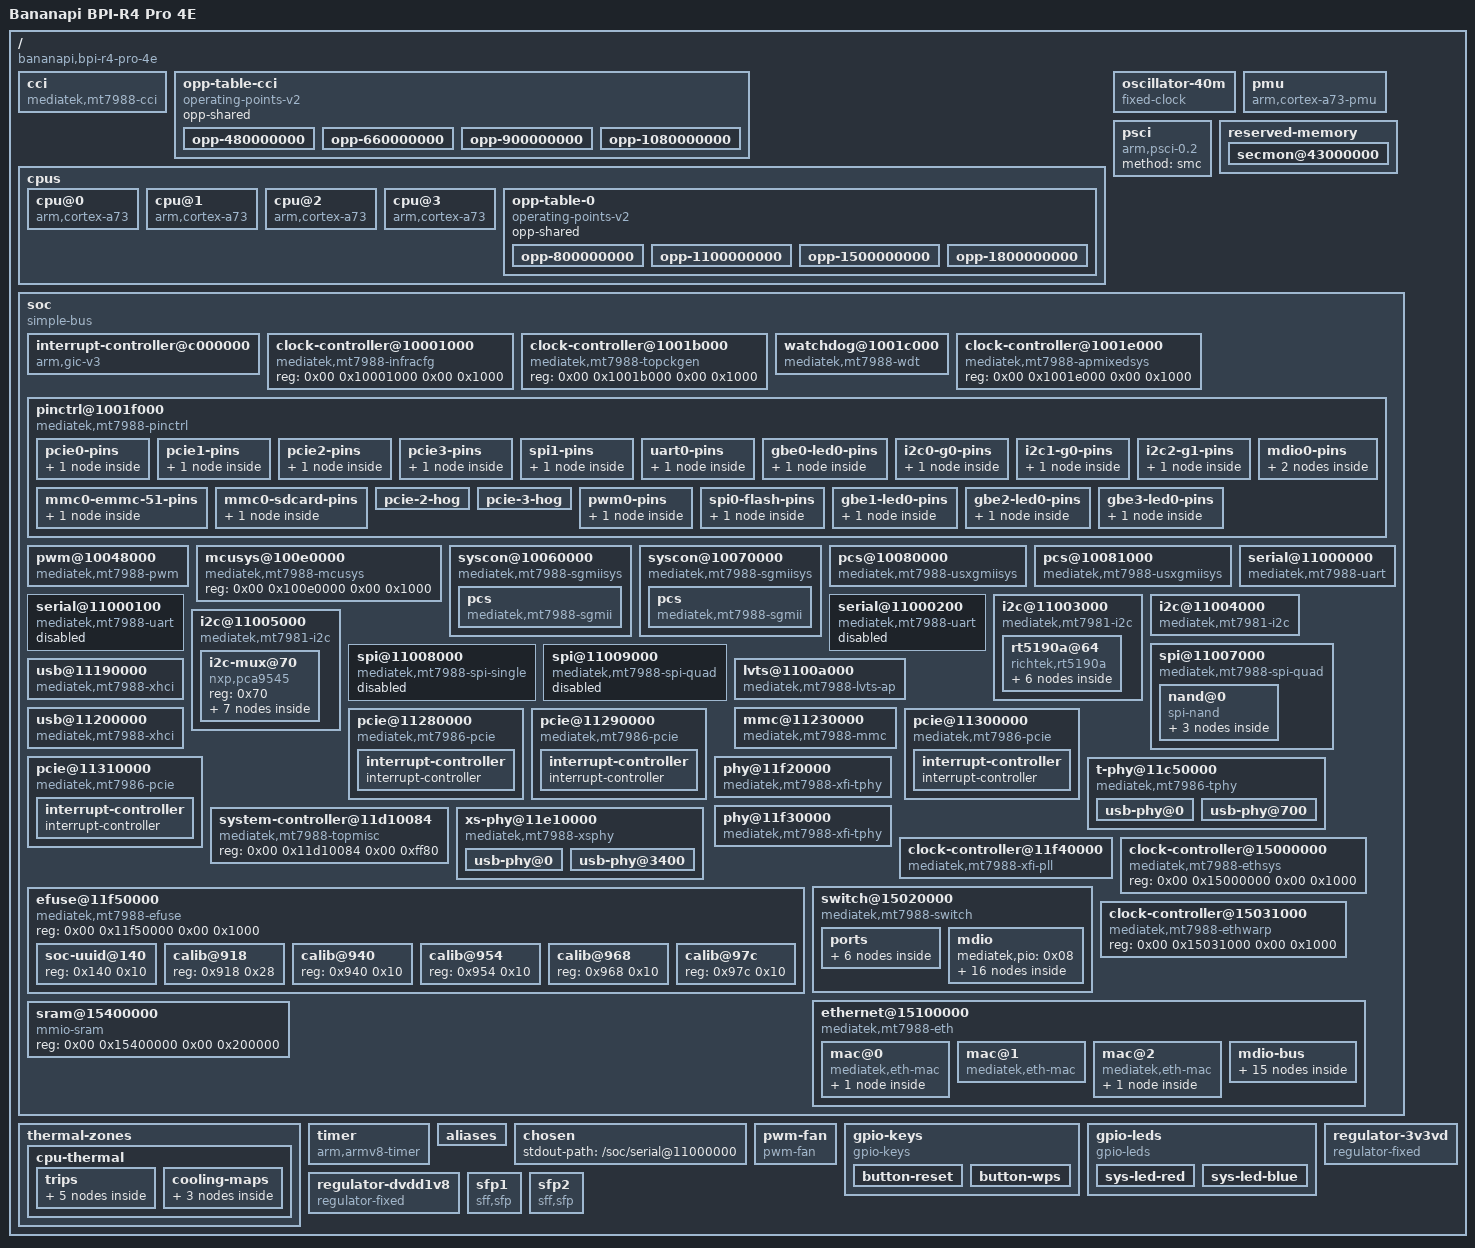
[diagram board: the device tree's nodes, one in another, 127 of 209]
/dts-v1/;

/ {
	compatible = "bananapi,bpi-r4-pro-4e", "bananapi,bpi-r4-pro", "mediatek,mt7988a";
	interrupt-parent = <0x01>;
	#address-cells = <0x02>;
	#size-cells = <0x02>;
	model = "Bananapi BPI-R4 Pro 4E";

	cci {
		compatible = "mediatek,mt7988-cci", "mediatek,mt8183-cci";
		clocks = <0x02 0x00 0x03 0x00>;
		clock-names = "cci", "intermediate";
		operating-points-v2 = <0x04>;
		proc-supply = <0x05>;
		phandle = <0x07>;
	};

	opp-table-cci {
		compatible = "operating-points-v2";
		opp-shared;
		phandle = <0x04>;

		opp-480000000 {
			opp-hz = <0x00 0x1c9c3800>;
			opp-microvolt = <0xcf850>;
		};

		opp-660000000 {
			opp-hz = <0x00 0x2756cd00>;
			opp-microvolt = <0xcf850>;
		};

		opp-900000000 {
			opp-hz = <0x00 0x35a4e900>;
			opp-microvolt = <0xcf850>;
		};

		opp-1080000000 {
			opp-hz = <0x00 0x405f7e00>;
			opp-microvolt = <0xdbba0>;
		};
	};

	cpus {
		#address-cells = <0x01>;
		#size-cells = <0x00>;

		cpu@0 {
			compatible = "arm,cortex-a73";
			reg = <0x00>;
			device_type = "cpu";
			enable-method = "psci";
			clocks = <0x02 0x01 0x03 0x00>;
			clock-names = "cpu", "intermediate";
			operating-points-v2 = <0x06>;
			mediatek,cci = <0x07>;
			proc-supply = <0x05>;
			phandle = <0x41>;
		};

		cpu@1 {
			compatible = "arm,cortex-a73";
			reg = <0x01>;
			device_type = "cpu";
			enable-method = "psci";
			clocks = <0x02 0x01 0x03 0x00>;
			clock-names = "cpu", "intermediate";
			operating-points-v2 = <0x06>;
			mediatek,cci = <0x07>;
			proc-supply = <0x05>;
			phandle = <0x42>;
		};

		cpu@2 {
			compatible = "arm,cortex-a73";
			reg = <0x02>;
			device_type = "cpu";
			enable-method = "psci";
			clocks = <0x02 0x01 0x03 0x00>;
			clock-names = "cpu", "intermediate";
			operating-points-v2 = <0x06>;
			mediatek,cci = <0x07>;
			proc-supply = <0x05>;
			phandle = <0x43>;
		};

		cpu@3 {
			compatible = "arm,cortex-a73";
			reg = <0x03>;
			device_type = "cpu";
			enable-method = "psci";
			clocks = <0x02 0x01 0x03 0x00>;
			clock-names = "cpu", "intermediate";
			operating-points-v2 = <0x06>;
			mediatek,cci = <0x07>;
			proc-supply = <0x05>;
			phandle = <0x44>;
		};

		opp-table-0 {
			compatible = "operating-points-v2";
			opp-shared;
			phandle = <0x06>;

			opp-800000000 {
				opp-hz = <0x00 0x2faf0800>;
				opp-microvolt = <0xcf850>;
			};

			opp-1100000000 {
				opp-hz = <0x00 0x4190ab00>;
				opp-microvolt = <0xcf850>;
			};

			opp-1500000000 {
				opp-hz = <0x00 0x59682f00>;
				opp-microvolt = <0xcf850>;
			};

			opp-1800000000 {
				opp-hz = <0x00 0x6b49d200>;
				opp-microvolt = <0xdbba0>;
			};
		};
	};

	oscillator-40m {
		compatible = "fixed-clock";
		clock-frequency = <0x2625a00>;
		#clock-cells = <0x00>;
		clock-output-names = "clkxtal";
	};

	pmu {
		compatible = "arm,cortex-a73-pmu";
		interrupt-parent = <0x01>;
		interrupts = <0x01 0x07 0x08>;
	};

	psci {
		compatible = "arm,psci-0.2";
		method = "smc";
	};

	reserved-memory {
		#address-cells = <0x02>;
		#size-cells = <0x02>;
		ranges;

		secmon@43000000 {
			reg = <0x00 0x43000000 0x00 0x50000>;
			no-map;
		};
	};

	soc {
		compatible = "simple-bus";
		ranges;
		#address-cells = <0x02>;
		#size-cells = <0x02>;

		interrupt-controller@c000000 {
			compatible = "arm,gic-v3";
			reg = <0x00 0xc000000 0x00 0x40000 0x00 0xc080000 0x00 0x200000 0x00 0xc400000 0x00 0x2000 0x00 0xc410000 0x00 0x1000 0x00 0xc420000 0x00 0x2000>;
			interrupt-parent = <0x01>;
			interrupts = <0x01 0x09 0x04>;
			interrupt-controller;
			#interrupt-cells = <0x03>;
			phandle = <0x01>;
		};

		clock-controller@10001000 {
			compatible = "mediatek,mt7988-infracfg", "syscon";
			reg = <0x00 0x10001000 0x00 0x1000>;
			#clock-cells = <0x01>;
			#reset-cells = <0x01>;
			phandle = <0x09>;
		};

		clock-controller@1001b000 {
			compatible = "mediatek,mt7988-topckgen", "syscon";
			reg = <0x00 0x1001b000 0x00 0x1000>;
			#clock-cells = <0x01>;
			phandle = <0x03>;
		};

		watchdog@1001c000 {
			compatible = "mediatek,mt7988-wdt";
			reg = <0x00 0x1001c000 0x00 0x1000>;
			interrupts = <0x00 0x6e 0x04>;
			#reset-cells = <0x01>;
			status = "okay";
			phandle = <0x21>;
		};

		clock-controller@1001e000 {
			compatible = "mediatek,mt7988-apmixedsys";
			reg = <0x00 0x1001e000 0x00 0x1000>;
			#clock-cells = <0x01>;
			phandle = <0x15>;
		};

		pinctrl@1001f000 {
			compatible = "mediatek,mt7988-pinctrl";
			reg = <0x00 0x1001f000 0x00 0x1000 0x00 0x11c10000 0x00 0x1000 0x00 0x11d00000 0x00 0x1000 0x00 0x11d20000 0x00 0x1000 0x00 0x11e00000 0x00 0x1000 0x00 0x11f00000 0x00 0x1000 0x00 0x1000b000 0x00 0x1000>;
			reg-names = "gpio", "iocfg_tr", "iocfg_br", "iocfg_rb", "iocfg_lb", "iocfg_tl", "eint";
			gpio-controller;
			#gpio-cells = <0x02>;
			gpio-ranges = <0x08 0x00 0x00 0x54>;
			interrupt-controller;
			interrupts = <0x00 0xe1 0x04>;
			interrupt-parent = <0x01>;
			#interrupt-cells = <0x02>;
			phandle = <0x08>;

			pcie0-pins {
				phandle = <0x1b>;

				mux {
					function = "pcie";
					groups = "pcie_2l_0_pereset", "pcie_clk_req_n0_0", "pcie_wake_n0_0";
				};
			};

			pcie1-pins {
				phandle = <0x1d>;

				mux {
					function = "pcie";
					groups = "pcie_2l_1_pereset", "pcie_clk_req_n1", "pcie_wake_n1_0";
				};
			};

			pcie2-pins {
				phandle = <0x16>;

				mux {
					function = "pcie";
					groups = "pcie_1l_0_pereset", "pcie_clk_req_n2_0", "pcie_wake_n2_0";
				};
			};

			pcie3-pins {
				phandle = <0x19>;

				mux {
					function = "pcie";
					groups = "pcie_1l_1_pereset", "pcie_clk_req_n3", "pcie_wake_n3_0";
				};
			};

			spi1-pins {
				phandle = <0x10>;

				mux {
					function = "spi";
					groups = "spi1";
				};
			};

			uart0-pins {
				phandle = <0x0a>;

				mux {
					function = "uart";
					groups = "uart0";
				};
			};

			gbe0-led0-pins {
				phandle = <0x29>;

				mux {
					function = "led";
					groups = "gbe0_led0";
				};
			};

			i2c0-g0-pins {
				phandle = <0x0b>;

				mux {
					function = "i2c";
					groups = "i2c0_1";
				};
			};

			i2c1-g0-pins {
				phandle = <0x0d>;

				mux {
					function = "i2c";
					groups = "i2c1_0";
				};
			};

			i2c2-g1-pins {
				phandle = <0x0e>;

				mux {
					function = "i2c";
					groups = "i2c2_1";
				};
			};

			mdio0-pins {
				phandle = <0x30>;

				mux {
					function = "eth";
					groups = "mdc_mdio0";
				};

				conf {
					pins = "SMI_0_MDC", "SMI_0_MDIO";
					drive-strength = <0x08>;
				};
			};

			mmc0-emmc-51-pins {
				phandle = <0x45>;

				mux {
					function = "flash";
					groups = "emmc_51";
				};
			};

			mmc0-sdcard-pins {
				phandle = <0x46>;

				mux {
					function = "flash";
					groups = "sdcard";
				};
			};

			pcie-2-hog {
				gpio-hog;
				gpios = <0x4f 0x00>;
			};

			pcie-3-hog {
				gpio-hog;
				gpios = <0x3f 0x00>;
			};

			pwm0-pins {
				phandle = <0x3c>;

				mux {
					groups = "pwm0";
					function = "pwm";
				};
			};

			spi0-flash-pins {
				phandle = <0x0f>;

				mux {
					function = "spi";
					groups = "spi0", "spi0_wp_hold";
				};
			};

			gbe1-led0-pins {
				phandle = <0x2b>;

				mux {
					function = "led";
					groups = "gbe1_led0";
				};
			};

			gbe2-led0-pins {
				phandle = <0x47>;

				mux {
					function = "led";
					groups = "gbe2_led0";
				};
			};

			gbe3-led0-pins {
				phandle = <0x48>;

				mux {
					function = "led";
					groups = "gbe3_led0";
				};
			};
		};

		pwm@10048000 {
			compatible = "mediatek,mt7988-pwm";
			reg = <0x00 0x10048000 0x00 0x1000>;
			clocks = <0x09 0x19 0x09 0x18 0x09 0x1a 0x09 0x1b 0x09 0x1c 0x09 0x1d 0x09 0x1e 0x09 0x1f 0x09 0x20 0x09 0x21>;
			clock-names = "top", "main", "pwm1", "pwm2", "pwm3", "pwm4", "pwm5", "pwm6", "pwm7", "pwm8";
			#pwm-cells = <0x02>;
			status = "okay";
			phandle = <0x3d>;
		};

		mcusys@100e0000 {
			compatible = "mediatek,mt7988-mcusys", "syscon";
			reg = <0x00 0x100e0000 0x00 0x1000>;
			#clock-cells = <0x01>;
			phandle = <0x02>;
		};

		/*
		 * SGMII / USXGMII SerDes PCS blocks.  The MACs bind these via
		 * pcs-handle; without them mtk_eth_soc logs
		 *   eth1: couldn't find a PCS for 10gbase-r
		 * and no WAN / MxL-CPU link comes up.  Node text mirrors the
		 * vendor / ly4096x board DTB.  The resets reference the
		 * TOPRGU (watchdog) reset controller (our phandle 0x21), NOT
		 * ethwarp: TOPRGU indices are SGMII0=1, SGMII1=2, XFI0=0x0c,
		 * XFI1=0x0d (MT7988_TOPRGU_SW_RST_NUM=24).
		 */
		syscon@10060000 {
			compatible = "mediatek,mt7988-sgmiisys", "mediatek,mt7988-sgmiisys0", "syscon", "simple-mfd";
			reg = <0x00 0x10060000 0x00 0x1000>;
			resets = <0x21 0x01>;
			#clock-cells = <0x01>;
			phandle = <0x80>;

			pcs {
				compatible = "mediatek,mt7988-sgmii";
				clocks = <0x03 0x43 0x80 0x00 0x80 0x01>;
				clock-names = "sgmii_sel", "sgmii_tx", "sgmii_rx";
				phys = <0x5e>;
				#pcs-cells = <0x00>;
				phandle = <0x81>;
			};
		};

		syscon@10070000 {
			compatible = "mediatek,mt7988-sgmiisys", "mediatek,mt7988-sgmiisys1", "syscon", "simple-mfd";
			reg = <0x00 0x10070000 0x00 0x1000>;
			resets = <0x21 0x02>;
			#clock-cells = <0x01>;
			phandle = <0x82>;

			pcs {
				compatible = "mediatek,mt7988-sgmii";
				clocks = <0x03 0x45 0x82 0x00 0x82 0x01>;
				clock-names = "sgmii_sel", "sgmii_tx", "sgmii_rx";
				phys = <0x5f>;
				#pcs-cells = <0x00>;
				phandle = <0x83>;
			};
		};

		pcs@10080000 {
			compatible = "mediatek,mt7988-usxgmiisys";
			reg = <0x00 0x10080000 0x00 0x1000>;
			resets = <0x21 0x0c>;
			clocks = <0x03 0x41>;
			phys = <0x5e>;
			#pcs-cells = <0x00>;
			phandle = <0x84>;
		};

		pcs@10081000 {
			compatible = "mediatek,mt7988-usxgmiisys";
			reg = <0x00 0x10081000 0x00 0x1000>;
			resets = <0x21 0x0d>;
			clocks = <0x03 0x42>;
			phys = <0x5f>;
			#pcs-cells = <0x00>;
			phandle = <0x85>;
		};

		serial@11000000 {
			compatible = "mediatek,mt7988-uart", "mediatek,mt6577-uart";
			reg = <0x00 0x11000000 0x00 0x100>;
			interrupts = <0x00 0x7b 0x04>;
			interrupt-names = "uart", "wakeup";
			clocks = <0x03 0x27 0x09 0x2f>;
			clock-names = "baud", "bus";
			pinctrl-names = "default";
			pinctrl-0 = <0x0a>;
			status = "okay";
			phandle = <0x49>;
		};

		serial@11000100 {
			compatible = "mediatek,mt7988-uart", "mediatek,mt6577-uart";
			reg = <0x00 0x11000100 0x00 0x100>;
			interrupts = <0x00 0x7c 0x04>;
			interrupt-names = "uart", "wakeup";
			clocks = <0x03 0x27 0x09 0x30>;
			clock-names = "baud", "bus";
			status = "disabled";
		};

		serial@11000200 {
			compatible = "mediatek,mt7988-uart", "mediatek,mt6577-uart";
			reg = <0x00 0x11000200 0x00 0x100>;
			interrupts = <0x00 0x7d 0x04>;
			interrupt-names = "uart", "wakeup";
			clocks = <0x03 0x27 0x09 0x31>;
			clock-names = "baud", "bus";
			status = "disabled";
		};

		i2c@11003000 {
			compatible = "mediatek,mt7981-i2c";
			reg = <0x00 0x11003000 0x00 0x1000 0x00 0x10217080 0x00 0x80>;
			interrupts = <0x00 0x88 0x04>;
			clock-div = <0x01>;
			clocks = <0x09 0x2e 0x09 0x2a>;
			clock-names = "main", "dma";
			#address-cells = <0x01>;
			#size-cells = <0x00>;
			status = "okay";
			pinctrl-0 = <0x0b>;
			pinctrl-names = "default";
			phandle = <0x4a>;

			rt5190a@64 {
				compatible = "richtek,rt5190a";
				reg = <0x64>;
				vin2-supply = <0x0c>;
				vin3-supply = <0x0c>;
				vin4-supply = <0x0c>;
				phandle = <0x4b>;

				regulators {

					buck1 {
						regulator-name = "rt5190a-buck1";
						regulator-min-microvolt = <0x4daad0>;
						regulator-max-microvolt = <0x4daad0>;
						regulator-allowed-modes = <0x00 0x01>;
						regulator-boot-on;
						regulator-always-on;
						phandle = <0x0c>;
					};

					buck2 {
						regulator-name = "vcore";
						regulator-min-microvolt = <0x927c0>;
						regulator-max-microvolt = <0x155cc0>;
						regulator-boot-on;
						regulator-always-on;
					};

					buck3 {
						regulator-name = "vproc";
						regulator-min-microvolt = <0x927c0>;
						regulator-max-microvolt = <0x155cc0>;
						regulator-boot-on;
						regulator-always-on;
						phandle = <0x05>;
					};

					buck4 {
						regulator-name = "rt5190a-buck4";
						regulator-min-microvolt = <0x1b7740>;
						regulator-max-microvolt = <0x1b7740>;
						regulator-allowed-modes = <0x00 0x01>;
						regulator-boot-on;
						regulator-always-on;
					};

					ldo {
						regulator-name = "rt5190a-ldo";
						regulator-min-microvolt = <0x1b7740>;
						regulator-max-microvolt = <0x1b7740>;
						regulator-boot-on;
						regulator-always-on;
					};
				};
			};
		};

		i2c@11004000 {
			compatible = "mediatek,mt7981-i2c";
			reg = <0x00 0x11004000 0x00 0x1000 0x00 0x10217100 0x00 0x80>;
			interrupts = <0x00 0x90 0x04>;
			clock-div = <0x01>;
			clocks = <0x09 0x2e 0x09 0x2a>;
			clock-names = "main", "dma";
			#address-cells = <0x01>;
			#size-cells = <0x00>;
			status = "okay";
			pinctrl-0 = <0x0d>;
			pinctrl-names = "default";
			phandle = <0x4c>;
		};

		i2c@11005000 {
			compatible = "mediatek,mt7981-i2c";
			reg = <0x00 0x11005000 0x00 0x1000 0x00 0x10217180 0x00 0x80>;
			interrupts = <0x00 0x91 0x04>;
			clock-div = <0x01>;
			clocks = <0x09 0x2e 0x09 0x2a>;
			clock-names = "main", "dma";
			#address-cells = <0x01>;
			#size-cells = <0x00>;
			status = "okay";
			pinctrl-0 = <0x0e>;
			pinctrl-names = "default";
			phandle = <0x4d>;

			i2c-mux@70 {
				compatible = "nxp,pca9545";
				reg = <0x70>;
				#address-cells = <0x01>;
				#size-cells = <0x00>;
				phandle = <0x4e>;

				i2c@0 {
					reg = <0x00>;
					#address-cells = <0x01>;
					#size-cells = <0x00>;
					phandle = <0x4f>;

					i2c-gpio-expander@20 {
						compatible = "nxp,pca9555";
						reg = <0x20>;
						gpio-controller;
						#gpio-cells = <0x02>;
						phandle = <0x3e>;
					};

					rtc@51 {
						compatible = "nxp,pcf8563";
						reg = <0x51>;
					};

					eeprom@57 {
						compatible = "atmel,24c02";
						reg = <0x57>;
						address-width = <0x08>;
						pagesize = <0x08>;
						size = <0x100>;
					};
				};

				i2c@1 {
					reg = <0x01>;
					#address-cells = <0x01>;
					#size-cells = <0x00>;
					phandle = <0x3f>;
				};

				i2c@2 {
					reg = <0x02>;
					#address-cells = <0x01>;
					#size-cells = <0x00>;
					phandle = <0x40>;
				};

				i2c@3 {
					reg = <0x03>;
					#address-cells = <0x01>;
					#size-cells = <0x00>;
					phandle = <0x50>;
				};
			};
		};

		spi@11007000 {
			compatible = "mediatek,mt7988-spi-quad", "mediatek,spi-ipm";
			reg = <0x00 0x11007000 0x00 0x100>;
			interrupts = <0x00 0x8c 0x04>;
			clocks = <0x03 0x04 0x03 0x2a 0x09 0x35 0x09 0x38>;
			clock-names = "parent-clk", "sel-clk", "spi-clk", "hclk";
			#address-cells = <0x01>;
			#size-cells = <0x00>;
			status = "okay";
			pinctrl-0 = <0x0f>;
			pinctrl-names = "default";
			phandle = <0x51>;

			nand@0 {
				compatible = "spi-nand";
				reg = <0x00>;
				spi-max-frequency = <0x3197500>;
				spi-rx-bus-width = <0x04>;
				spi-tx-bus-width = <0x04>;
				phandle = <0x52>;

				partitions {
					compatible = "fixed-partitions";
					#address-cells = <0x01>;
					#size-cells = <0x01>;

					partition@0 {
						reg = <0x00 0x200000>;
						label = "bl2";
					};

					partition@200000 {
						compatible = "linux,ubi";
						reg = <0x200000 0xfe00000>;
						label = "ubi";
					};
				};
			};
		};

		spi@11008000 {
			compatible = "mediatek,mt7988-spi-single", "mediatek,spi-ipm";
			reg = <0x00 0x11008000 0x00 0x100>;
			interrupts = <0x00 0x8d 0x04>;
			clocks = <0x03 0x04 0x03 0x2b 0x09 0x36 0x09 0x39>;
			clock-names = "parent-clk", "sel-clk", "spi-clk", "hclk";
			#address-cells = <0x01>;
			#size-cells = <0x00>;
			pinctrl-names = "default";
			pinctrl-0 = <0x10>;
			status = "disabled";
			phandle = <0x53>;
		};

		spi@11009000 {
			compatible = "mediatek,mt7988-spi-quad", "mediatek,spi-ipm";
			reg = <0x00 0x11009000 0x00 0x100>;
			interrupts = <0x00 0x8e 0x04>;
			clocks = <0x03 0x04 0x03 0x2a 0x09 0x37 0x09 0x3a>;
			clock-names = "parent-clk", "sel-clk", "spi-clk", "hclk";
			#address-cells = <0x01>;
			#size-cells = <0x00>;
			status = "disabled";
			phandle = <0x54>;
		};

		lvts@1100a000 {
			compatible = "mediatek,mt7988-lvts-ap";
			#thermal-sensor-cells = <0x01>;
			reg = <0x00 0x1100a000 0x00 0x1000>;
			clocks = <0x09 0x2d>;
			interrupts = <0x00 0x8a 0x04>;
			resets = <0x09 0x01>;
			nvmem-cells = <0x11>;
			nvmem-cell-names = "lvts-calib-data-1";
			phandle = <0x37>;
		};

		usb@11190000 {
			compatible = "mediatek,mt7988-xhci", "mediatek,mtk-xhci";
			reg = <0x00 0x11190000 0x00 0x2e00 0x00 0x11193e00 0x00 0x100>;
			reg-names = "mac", "ippc";
			interrupts = <0x00 0xad 0x04>;
			clocks = <0x09 0x4b 0x09 0x4d 0x09 0x49 0x09 0x47 0x09 0x55>;
			clock-names = "sys_ck", "ref_ck", "mcu_ck", "dma_ck", "xhci_ck";
			phys = <0x12 0x03>;
			status = "okay";
			mediatek,u3p-dis-msk = <0x01>;
			phandle = <0x55>;
		};

		usb@11200000 {
			compatible = "mediatek,mt7988-xhci", "mediatek,mtk-xhci";
			reg = <0x00 0x11200000 0x00 0x2e00 0x00 0x11203e00 0x00 0x100>;
			reg-names = "mac", "ippc";
			interrupts = <0x00 0xac 0x04>;
			clocks = <0x09 0x4c 0x09 0x4e 0x09 0x4a 0x09 0x48 0x09 0x56>;
			clock-names = "sys_ck", "ref_ck", "mcu_ck", "dma_ck", "xhci_ck";
			phys = <0x13 0x03 0x14 0x04>;
			status = "okay";
			phandle = <0x56>;
		};

		mmc@11230000 {
			no-mmc;
			vqmmc-supply = <0x77>;
			vmmc-supply = <0x77>;
			cap-sd-highspeed;
			max-frequency = <0x2dc6c00>;
			bus-width = <0x04>;
			cd-gpios = <0x08 0x0c 0x01>;
			pinctrl-1 = <0x46>;
			pinctrl-0 = <0x46>;
			pinctrl-names = "default", "state_uhs";
			compatible = "mediatek,mt7988-mmc";
			reg = <0x00 0x11230000 0x00 0x1000 0x00 0x11d60000 0x00 0x1000>;
			interrupts = <0x00 0x8f 0x04>;
			clocks = <0x09 0x3f 0x09 0x40 0x09 0x42 0x09 0x41>;
			assigned-clocks = <0x03 0x28 0x03 0x29>;
			assigned-clock-parents = <0x03 0x11 0x15 0x0b>;
			clock-names = "source", "hclk", "axi_cg", "ahb_cg";
			#address-cells = <0x01>;
			#size-cells = <0x00>;
			status = "okay";
			phandle = <0x57>;
		};

		pcie@11280000 {
			compatible = "mediatek,mt7986-pcie", "mediatek,mt8192-pcie";
			device_type = "pci";
			#address-cells = <0x03>;
			#size-cells = <0x02>;
			reg = <0x00 0x11280000 0x00 0x2000>;
			reg-names = "pcie-mac";
			linux,pci-domain = <0x03>;
			interrupts = <0x00 0xaa 0x04>;
			bus-range = <0x00 0xff>;
			ranges = <0x81000000 0x00 0x20000000 0x00 0x20000000 0x00 0x200000 0x82000000 0x00 0x20200000 0x00 0x20200000 0x00 0x7e00000>;
			clocks = <0x09 0x5d 0x09 0x59 0x09 0x15 0x09 0x61>;
			clock-names = "pl_250m", "tl_26m", "peri_26m", "top_133m";
			pinctrl-names = "default";
			pinctrl-0 = <0x16>;
			status = "okay";
			phys = <0x17 0x02>;
			phy-names = "pcie-phy";
			#interrupt-cells = <0x01>;
			interrupt-map-mask = <0x00 0x00 0x00 0x07>;
			interrupt-map = <0x00 0x00 0x00 0x01 0x18 0x00 0x00 0x00 0x00 0x02 0x18 0x01 0x00 0x00 0x00 0x03 0x18 0x02 0x00 0x00 0x00 0x04 0x18 0x03>;
			phandle = <0x58>;

			interrupt-controller {
				#address-cells = <0x00>;
				#interrupt-cells = <0x01>;
				interrupt-controller;
				phandle = <0x18>;
			};
		};

		pcie@11290000 {
			compatible = "mediatek,mt7986-pcie", "mediatek,mt8192-pcie";
			device_type = "pci";
			#address-cells = <0x03>;
			#size-cells = <0x02>;
			reg = <0x00 0x11290000 0x00 0x2000>;
			reg-names = "pcie-mac";
			linux,pci-domain = <0x02>;
			interrupts = <0x00 0xab 0x04>;
			bus-range = <0x00 0xff>;
			ranges = <0x81000000 0x00 0x28000000 0x00 0x28000000 0x00 0x200000 0x82000000 0x00 0x28200000 0x00 0x28200000 0x00 0x7e00000>;
			clocks = <0x09 0x5e 0x09 0x5a 0x09 0x16 0x09 0x62>;
			clock-names = "pl_250m", "tl_26m", "peri_26m", "top_133m";
			pinctrl-names = "default";
			pinctrl-0 = <0x19>;
			status = "okay";
			#interrupt-cells = <0x01>;
			interrupt-map-mask = <0x00 0x00 0x00 0x07>;
			interrupt-map = <0x00 0x00 0x00 0x01 0x1a 0x00 0x00 0x00 0x00 0x02 0x1a 0x01 0x00 0x00 0x00 0x03 0x1a 0x02 0x00 0x00 0x00 0x04 0x1a 0x03>;
			phandle = <0x59>;

			interrupt-controller {
				#address-cells = <0x00>;
				#interrupt-cells = <0x01>;
				interrupt-controller;
				phandle = <0x1a>;
			};
		};

		pcie@11300000 {
			compatible = "mediatek,mt7986-pcie", "mediatek,mt8192-pcie";
			device_type = "pci";
			#address-cells = <0x03>;
			#size-cells = <0x02>;
			reg = <0x00 0x11300000 0x00 0x2000>;
			reg-names = "pcie-mac";
			linux,pci-domain = <0x00>;
			interrupts = <0x00 0xa8 0x04>;
			bus-range = <0x00 0xff>;
			ranges = <0x81000000 0x00 0x30000000 0x00 0x30000000 0x00 0x200000 0x82000000 0x00 0x30200000 0x00 0x30200000 0x00 0x7e00000>;
			clocks = <0x09 0x5b 0x09 0x57 0x09 0x13 0x09 0x5f>;
			clock-names = "pl_250m", "tl_26m", "peri_26m", "top_133m";
			pinctrl-names = "default";
			pinctrl-0 = <0x1b>;
			status = "okay";
			#interrupt-cells = <0x01>;
			interrupt-map-mask = <0x00 0x00 0x00 0x07>;
			interrupt-map = <0x00 0x00 0x00 0x01 0x1c 0x00 0x00 0x00 0x00 0x02 0x1c 0x01 0x00 0x00 0x00 0x03 0x1c 0x02 0x00 0x00 0x00 0x04 0x1c 0x03>;
			phandle = <0x5a>;

			interrupt-controller {
				#address-cells = <0x00>;
				#interrupt-cells = <0x01>;
				interrupt-controller;
				phandle = <0x1c>;
			};
		};

		pcie@11310000 {
			compatible = "mediatek,mt7986-pcie", "mediatek,mt8192-pcie";
			device_type = "pci";
			#address-cells = <0x03>;
			#size-cells = <0x02>;
			reg = <0x00 0x11310000 0x00 0x2000>;
			reg-names = "pcie-mac";
			linux,pci-domain = <0x01>;
			interrupts = <0x00 0xa9 0x04>;
			bus-range = <0x00 0xff>;
			ranges = <0x81000000 0x00 0x38000000 0x00 0x38000000 0x00 0x200000 0x82000000 0x00 0x38200000 0x00 0x38200000 0x00 0x7e00000>;
			clocks = <0x09 0x5c 0x09 0x58 0x09 0x14 0x09 0x60>;
			clock-names = "pl_250m", "tl_26m", "peri_26m", "top_133m";
			pinctrl-names = "default";
			pinctrl-0 = <0x1d>;
			status = "okay";
			#interrupt-cells = <0x01>;
			interrupt-map-mask = <0x00 0x00 0x00 0x07>;
			interrupt-map = <0x00 0x00 0x00 0x01 0x1e 0x00 0x00 0x00 0x00 0x02 0x1e 0x01 0x00 0x00 0x00 0x03 0x1e 0x02 0x00 0x00 0x00 0x04 0x1e 0x03>;
			phandle = <0x5b>;

			interrupt-controller {
				#address-cells = <0x00>;
				#interrupt-cells = <0x01>;
				interrupt-controller;
				phandle = <0x1e>;
			};
		};

		t-phy@11c50000 {
			compatible = "mediatek,mt7986-tphy", "mediatek,generic-tphy-v2";
			#address-cells = <0x01>;
			#size-cells = <0x01>;
			ranges = <0x00 0x00 0x11c50000 0x1000>;
			status = "okay";
			phandle = <0x5c>;

			usb-phy@0 {
				reg = <0x00 0x700>;
				clocks = <0x09 0x54>;
				clock-names = "ref";
				#phy-cells = <0x01>;
				phandle = <0x13>;
			};

			usb-phy@700 {
				reg = <0x700 0x900>;
				clocks = <0x09 0x52>;
				clock-names = "ref";
				#phy-cells = <0x01>;
				phandle = <0x14>;
			};
		};

		system-controller@11d10084 {
			compatible = "mediatek,mt7988-topmisc", "syscon";
			reg = <0x00 0x11d10084 0x00 0xff80>;
			phandle = <0x1f>;
		};

		xs-phy@11e10000 {
			compatible = "mediatek,mt7988-xsphy", "mediatek,xsphy";
			#address-cells = <0x01>;
			#size-cells = <0x01>;
			ranges = <0x00 0x00 0x11e10000 0x3900>;
			status = "okay";
			phandle = <0x5d>;

			usb-phy@0 {
				reg = <0x00 0x400>;
				clocks = <0x09 0x53>;
				clock-names = "ref";
				#phy-cells = <0x01>;
				phandle = <0x12>;
			};

			usb-phy@3400 {
				reg = <0x3400 0x500>;
				clocks = <0x09 0x51>;
				clock-names = "ref";
				#phy-cells = <0x01>;
				mediatek,syscon-type = <0x1f 0x194 0x00>;
				phandle = <0x17>;
			};
		};

		phy@11f20000 {
			compatible = "mediatek,mt7988-xfi-tphy";
			reg = <0x00 0x11f20000 0x00 0x10000>;
			clocks = <0x20 0x01 0x03 0x47>;
			clock-names = "xfipll", "topxtal";
			resets = <0x21 0x0e>;
			mediatek,usxgmii-performance-errata;
			#phy-cells = <0x00>;
			phandle = <0x5e>;
		};

		phy@11f30000 {
			compatible = "mediatek,mt7988-xfi-tphy";
			reg = <0x00 0x11f30000 0x00 0x10000>;
			clocks = <0x20 0x01 0x03 0x48>;
			clock-names = "xfipll", "topxtal";
			resets = <0x21 0x0f>;
			#phy-cells = <0x00>;
			phandle = <0x5f>;
		};

		clock-controller@11f40000 {
			compatible = "mediatek,mt7988-xfi-pll";
			reg = <0x00 0x11f40000 0x00 0x1000>;
			resets = <0x21 0x10>;
			#clock-cells = <0x01>;
			phandle = <0x20>;
		};

		efuse@11f50000 {
			compatible = "mediatek,mt7988-efuse", "mediatek,efuse";
			reg = <0x00 0x11f50000 0x00 0x1000>;
			#address-cells = <0x01>;
			#size-cells = <0x01>;

			soc-uuid@140 {
				reg = <0x140 0x10>;
			};

			calib@918 {
				reg = <0x918 0x28>;
				phandle = <0x11>;
			};

			calib@940 {
				reg = <0x940 0x10>;
				phandle = <0x28>;
			};

			calib@954 {
				reg = <0x954 0x10>;
				phandle = <0x2a>;
			};

			calib@968 {
				reg = <0x968 0x10>;
				phandle = <0x2c>;
			};

			calib@97c {
				reg = <0x97c 0x10>;
				phandle = <0x2d>;
			};
		};

		clock-controller@15000000 {
			compatible = "mediatek,mt7988-ethsys", "syscon";
			reg = <0x00 0x15000000 0x00 0x1000>;
			#clock-cells = <0x01>;
			#reset-cells = <0x01>;
			phandle = <0x2e>;
		};

		switch@15020000 {
			compatible = "mediatek,mt7988-switch";
			reg = <0x00 0x15020000 0x00 0x8000>;
			interrupt-controller;
			#interrupt-cells = <0x01>;
			interrupts = <0x00 0xd1 0x04>;
			resets = <0x22 0x00>;
			dsa,member = <0x01 0x00>;
			status = "okay";
			phandle = <0x60>;

			ports {
				#address-cells = <0x01>;
				#size-cells = <0x00>;

				port@0 {
					reg = <0x00>;
					phy-handle = <0x23>;
					phy-mode = "internal";
					label = "lan5";
					phandle = <0x61>;
				};

				port@1 {
					reg = <0x01>;
					phy-handle = <0x24>;
					phy-mode = "internal";
					status = "disabled";
					phandle = <0x62>;
				};

				port@2 {
					reg = <0x02>;
					phy-handle = <0x25>;
					phy-mode = "internal";
					status = "disabled";
					phandle = <0x63>;
				};

				port@3 {
					reg = <0x03>;
					phy-handle = <0x26>;
					phy-mode = "internal";
					status = "disabled";
					phandle = <0x64>;
				};

				port@6 {
					reg = <0x06>;
					ethernet = <0x27>;
					phy-mode = "internal";

					fixed-link {
						speed = <0x2710>;
						full-duplex;
						pause;
					};
				};
			};

			mdio {
				#address-cells = <0x01>;
				#size-cells = <0x00>;
				mediatek,pio = <0x08>;

				ethernet-phy@0 {
					compatible = "ethernet-phy-ieee802.3-c22";
					reg = <0x00>;
					interrupts = <0x00>;
					nvmem-cells = <0x28>;
					nvmem-cell-names = "phy-cal-data";
					pinctrl-0 = <0x29>;
					pinctrl-names = "gbe-led";
					phandle = <0x23>;

					leds {
						#address-cells = <0x01>;
						#size-cells = <0x00>;

						led@0 {
							reg = <0x00>;
							status = "okay";
							color = <0x06>;
							phandle = <0x65>;
						};

						led@1 {
							reg = <0x01>;
							status = "disabled";
							phandle = <0x66>;
						};
					};
				};

				ethernet-phy@1 {
					compatible = "ethernet-phy-ieee802.3-c22";
					reg = <0x01>;
					interrupts = <0x01>;
					nvmem-cells = <0x2a>;
					nvmem-cell-names = "phy-cal-data";
					status = "okay";
					pinctrl-names = "gbe-led";
					pinctrl-0 = <0x2b>;
					phandle = <0x24>;

					leds {
						#address-cells = <0x01>;
						#size-cells = <0x00>;

						led@0 {
							reg = <0x00>;
							status = "disabled";
							phandle = <0x67>;
						};

						led@1 {
							reg = <0x01>;
							status = "disabled";
							phandle = <0x68>;
						};
					};
				};

				ethernet-phy@2 {
					compatible = "ethernet-phy-ieee802.3-c22";
					reg = <0x02>;
					interrupts = <0x02>;
					nvmem-cells = <0x2c>;
					nvmem-cell-names = "phy-cal-data";
					status = "disabled";
					phandle = <0x25>;

					leds {
						#address-cells = <0x01>;
						#size-cells = <0x00>;

						led@0 {
							reg = <0x00>;
							status = "disabled";
							phandle = <0x69>;
						};

						led@1 {
							reg = <0x01>;
							status = "disabled";
							phandle = <0x6a>;
						};
					};
				};

				ethernet-phy@3 {
					compatible = "ethernet-phy-ieee802.3-c22";
					reg = <0x03>;
					interrupts = <0x03>;
					nvmem-cells = <0x2d>;
					nvmem-cell-names = "phy-cal-data";
					status = "disabled";
					phandle = <0x26>;

					leds {
						#address-cells = <0x01>;
						#size-cells = <0x00>;

						led@0 {
							reg = <0x00>;
							status = "disabled";
							phandle = <0x6b>;
						};

						led@1 {
							reg = <0x01>;
							status = "disabled";
							phandle = <0x6c>;
						};
					};
				};
			};
		};

		clock-controller@15031000 {
			compatible = "mediatek,mt7988-ethwarp";
			reg = <0x00 0x15031000 0x00 0x1000>;
			#clock-cells = <0x01>;
			#reset-cells = <0x01>;
			phandle = <0x22>;
		};

		ethernet@15100000 {
			compatible = "mediatek,mt7988-eth";
			reg = <0x00 0x15100000 0x00 0x40000>;
			interrupts = <0x00 0xc4 0x04 0x00 0xc5 0x04 0x00 0xc6 0x04 0x00 0xc7 0x04 0x00 0xbd 0x04 0x00 0xbe 0x04 0x00 0xbf 0x04 0x00 0xc0 0x04>;
			interrupt-names = "fe0", "fe1", "fe2", "fe3", "pdma0", "pdma1", "pdma2", "pdma3";
			clocks = <0x2e 0x08 0x2e 0x03 0x2e 0x04 0x2e 0x05 0x2e 0x06 0x22 0x00 0x22 0x01 0x22 0x02 0x2e 0x07 0x03 0x22 0x03 0x4b 0x03 0x4c 0x03 0x4d 0x03 0x4e 0x03 0x66 0x03 0x1e 0x03 0x1f 0x03 0x24 0x03 0x61 0x03 0x64 0x03 0x65 0x2e 0x00 0x2e 0x01 0x2e 0x02>;
			clock-names = "crypto", "fe", "gp2", "gp1", "gp3", "ethwarp_wocpu2", "ethwarp_wocpu1", "ethwarp_wocpu0", "esw", "top_eth_gmii_sel", "top_eth_refck_50m_sel", "top_eth_sys_200m_sel", "top_eth_sys_sel", "top_eth_xgmii_sel", "top_eth_mii_sel", "top_netsys_sel", "top_netsys_500m_sel", "top_netsys_pao_2x_sel", "top_netsys_sync_250m_sel", "top_netsys_ppefb_250m_sel", "top_netsys_warp_sel", "xgp1", "xgp2", "xgp3";
			assigned-clocks = <0x03 0x20 0x03 0x21 0x03 0x41 0x03 0x42 0x03 0x43 0x03 0x45>;
			assigned-clock-parents = <0x15 0x05 0x03 0x0f 0x03 0x15 0x03 0x15 0x15 0x07 0x15 0x07>;
			sram = <0x2f>;
			#address-cells = <0x01>;
			#size-cells = <0x00>;
			mediatek,ethsys = <0x2e>;
			mediatek,infracfg = <0x1f>;
			pinctrl-0 = <0x30>;
			pinctrl-names = "default";
			status = "okay";
			phandle = <0x6d>;

			mac@0 {
				compatible = "mediatek,eth-mac";
				reg = <0x00>;
				phy-mode = "internal";
				status = "okay";
				phandle = <0x27>;

				fixed-link {
					speed = <0x2710>;
					full-duplex;
					pause;
				};
			};

			mac@1 {
				compatible = "mediatek,eth-mac";
				reg = <0x01>;
				/* WAN = USXGMII1 -> the sfp2 cage (vendor "-sfp" board
				   overlay).  Vendor-exact WAN binding: in-band status +
				   10gbase-r + sfp2.  The vendor ships a "-iphy" overlay
				   for the 2.5G RJ45 WAN instead. */
				status = "okay";
				managed = "in-band-status";
				phy-mode = "10gbase-r";
				phy-connection-type = "10gbase-r";
				pcs-handle = <0x81 0x85>;
				sfp = <0x78>;
				phandle = <0x6e>;
			};

			mac@2 {
				compatible = "mediatek,eth-mac";
				reg = <0x02>;
				status = "okay";
				phy-mode = "10gbase-r";
				phy-connection-type = "10gbase-r";
				pcs-handle = <0x83 0x84>;
				phandle = <0x35>;

				fixed-link {
					speed = <0x2710>;
					full-duplex;
				};
			};

			mdio-bus {
				#address-cells = <0x01>;
				#size-cells = <0x00>;
				phandle = <0x6f>;

				ethernet-phy@15 {
					compatible = "ethernet-phy-ieee802.3-c45";
					reg = <0x0f>;
					status = "disabled";
					phandle = <0x70>;
				};

				switch@16 {
					compatible = "maxlinear,mxl86252";
					reg = <0x10>;
					dsa,member = <0x00 0x00>;
					status = "okay";

					ports {
						#address-cells = <0x01>;
						#size-cells = <0x00>;

						port@1 {
							reg = <0x01>;
							label = "mxl_lan0";
							phy-handle = <0x31>;
							phy-mode = "internal";
							status = "okay";
						};

						port@2 {
							reg = <0x02>;
							label = "mxl_lan1";
							phy-handle = <0x32>;
							phy-mode = "internal";
							status = "okay";
						};

						port@3 {
							reg = <0x03>;
							label = "mxl_lan2";
							phy-handle = <0x33>;
							phy-mode = "internal";
							status = "okay";
						};

						port@4 {
							reg = <0x04>;
							label = "mxl_lan3";
							phy-handle = <0x34>;
							phy-mode = "internal";
							status = "okay";
						};

						port@9 {
							reg = <0x09>;
							label = "cpu";
							phy-mode = "usxgmii";
							ethernet = <0x35>;

							fixed-link {
								speed = <0x2710>;
								full-duplex;
							};
						};

						port@13 {
							reg = <0x0d>;
							label = "mxl_lan5";
							phy-mode = "usxgmii";
							managed = "in-band-status";
							sfp = <0x36>;
							status = "okay";
						};
					};

					mdio {
						#address-cells = <0x01>;
						#size-cells = <0x00>;

						switchphy@0 {
							reg = <0x00>;
							phandle = <0x31>;
						};

						switchphy@1 {
							reg = <0x01>;
							phandle = <0x32>;
						};

						switchphy@2 {
							reg = <0x02>;
							phandle = <0x33>;
						};

						switchphy@3 {
							reg = <0x03>;
							phandle = <0x34>;
						};
					};
				};
			};
		};

		sram@15400000 {
			compatible = "mmio-sram";
			reg = <0x00 0x15400000 0x00 0x200000>;
			#address-cells = <0x01>;
			#size-cells = <0x01>;
			ranges = <0x00 0x15400000 0x00 0x200000>;
			phandle = <0x2f>;
		};
	};

	thermal-zones {

		cpu-thermal {
			polling-delay-passive = <0x3e8>;
			polling-delay = <0x3e8>;
			thermal-sensors = <0x37 0x00>;
			phandle = <0x71>;

			trips {

				crit {
					temperature = <0x1e848>;
					hysteresis = <0x7d0>;
					type = "critical";
					phandle = <0x72>;
				};

				hot {
					temperature = <0x1d4c0>;
					hysteresis = <0x7d0>;
					type = "hot";
					phandle = <0x73>;
				};

				active-high {
					temperature = <0x1c138>;
					hysteresis = <0x7d0>;
					type = "active";
					phandle = <0x39>;
				};

				active-med {
					temperature = <0x14c08>;
					hysteresis = <0x7d0>;
					type = "active";
					phandle = <0x3a>;
				};

				active-low {
					temperature = <0x9c40>;
					hysteresis = <0x7d0>;
					type = "active";
					phandle = <0x3b>;
				};
			};

			cooling-maps {

				map-cpu-active-high {
					cooling-device = <0x38 0x03 0x03>;
					trip = <0x39>;
				};

				map-cpu-active-med {
					cooling-device = <0x38 0x02 0x02>;
					trip = <0x3a>;
				};

				map-cpu-active-low {
					cooling-device = <0x38 0x01 0x01>;
					trip = <0x3b>;
				};
			};
		};
	};

	timer {
		compatible = "arm,armv8-timer";
		interrupt-parent = <0x01>;
		interrupts = <0x01 0x0d 0x08 0x01 0x0e 0x08 0x01 0x0b 0x08 0x01 0x0a 0x08>;
	};

	aliases {
		ethernet0 = "/soc/ethernet@15100000/mac@0";
		i2c0 = "/soc/i2c@11003000";
		i2c1 = "/soc/i2c@11004000";
		i2c2 = "/soc/i2c@11005000";
		i2c3 = "/soc/i2c@11005000/i2c-mux@70/i2c@0";
		i2c4 = "/soc/i2c@11005000/i2c-mux@70/i2c@1";
		i2c5 = "/soc/i2c@11005000/i2c-mux@70/i2c@2";
		i2c6 = "/soc/i2c@11005000/i2c-mux@70/i2c@3";
	};

	chosen {
		stdout-path = "/soc/serial@11000000";
	};

	pwm-fan {
		compatible = "pwm-fan";
		cooling-levels = <0x00 0x50 0x80 0xff>;
		pinctrl-0 = <0x3c>;
		pinctrl-names = "default";
		pwms = <0x3d 0x00 0xc350>;
		#cooling-cells = <0x02>;
		phandle = <0x38>;
	};

	gpio-keys {
		compatible = "gpio-keys";

		button-reset {
			label = "reset";
			gpios = <0x08 0x0d 0x01>;
			linux,code = <0x198>;
		};

		button-wps {
			label = "WPS";
			gpios = <0x08 0x0e 0x01>;
			linux,code = <0x211>;
		};
	};

	gpio-leds {
		compatible = "gpio-leds";

		sys-led-red {
			color = <0x01>;
			function = "fault";
			gpios = <0x3e 0x0f 0x00>;
			phandle = <0x74>;
		};

		sys-led-blue {
			color = <0x03>;
			function = "activity";
			gpios = <0x3e 0x0e 0x00>;
			phandle = <0x75>;
		};
	};

	regulator-dvdd1v8 {
		compatible = "regulator-fixed";
		regulator-name = "DVDD1V8_SOC";
		regulator-min-microvolt = <0x1b7740>;
		regulator-max-microvolt = <0x1b7740>;
		regulator-boot-on;
		regulator-always-on;
		phandle = <0x76>;
	};

	regulator-3v3vd {
		compatible = "regulator-fixed";
		regulator-name = "3V3VD";
		regulator-min-microvolt = <0x325aa0>;
		regulator-max-microvolt = <0x325aa0>;
		regulator-boot-on;
		regulator-always-on;
		phandle = <0x77>;
	};

	sfp1 {
		compatible = "sff,sfp";
		i2c-bus = <0x3f>;
		los-gpios = <0x08 0x46 0x00>;
		mod-def0-gpios = <0x08 0x45 0x01>;
		tx-disable-gpios = <0x08 0x15 0x00>;
		maximum-power-milliwatt = <0xbb8>;
		phandle = <0x36>;
	};

	sfp2 {
		compatible = "sff,sfp";
		i2c-bus = <0x40>;
		los-gpios = <0x08 0x02 0x00>;
		mod-def0-gpios = <0x08 0x01 0x01>;
		tx-disable-gpios = <0x08 0x00 0x00>;
		maximum-power-milliwatt = <0xbb8>;
		phandle = <0x78>;
	};

	__symbols__ {
		cci = "/cci";
		cci_opp = "/opp-table-cci";
		cpu0 = "/cpus/cpu@0";
		cpu1 = "/cpus/cpu@1";
		cpu2 = "/cpus/cpu@2";
		cpu3 = "/cpus/cpu@3";
		cluster0_opp = "/cpus/opp-table-0";
		gic = "/soc/interrupt-controller@c000000";
		infracfg = "/soc/clock-controller@10001000";
		topckgen = "/soc/clock-controller@1001b000";
		watchdog = "/soc/watchdog@1001c000";
		apmixedsys = "/soc/clock-controller@1001e000";
		pio = "/soc/pinctrl@1001f000";
		pcie0_pins = "/soc/pinctrl@1001f000/pcie0-pins";
		pcie1_pins = "/soc/pinctrl@1001f000/pcie1-pins";
		pcie2_pins = "/soc/pinctrl@1001f000/pcie2-pins";
		pcie3_pins = "/soc/pinctrl@1001f000/pcie3-pins";
		spi1_pins = "/soc/pinctrl@1001f000/spi1-pins";
		uart0_pins = "/soc/pinctrl@1001f000/uart0-pins";
		gbe0_led0_pins = "/soc/pinctrl@1001f000/gbe0-led0-pins";
		i2c0_pins = "/soc/pinctrl@1001f000/i2c0-g0-pins";
		i2c1_pins = "/soc/pinctrl@1001f000/i2c1-g0-pins";
		i2c2_1_pins = "/soc/pinctrl@1001f000/i2c2-g1-pins";
		mdio0_pins = "/soc/pinctrl@1001f000/mdio0-pins";
		mmc0_pins_emmc_51 = "/soc/pinctrl@1001f000/mmc0-emmc-51-pins";
		mmc0_pins_sdcard = "/soc/pinctrl@1001f000/mmc0-sdcard-pins";
		pwm0_pins = "/soc/pinctrl@1001f000/pwm0-pins";
		spi0_flash_pins = "/soc/pinctrl@1001f000/spi0-flash-pins";
		gbe1_led0_pins = "/soc/pinctrl@1001f000/gbe1-led0-pins";
		gbe2_led0_pins = "/soc/pinctrl@1001f000/gbe2-led0-pins";
		gbe3_led0_pins = "/soc/pinctrl@1001f000/gbe3-led0-pins";
		pwm = "/soc/pwm@10048000";
		mcusys = "/soc/mcusys@100e0000";
		serial0 = "/soc/serial@11000000";
		i2c0 = "/soc/i2c@11003000";
		rt5190a_64 = "/soc/i2c@11003000/rt5190a@64";
		rt5190_buck1 = "/soc/i2c@11003000/rt5190a@64/regulators/buck1";
		rt5190_buck3 = "/soc/i2c@11003000/rt5190a@64/regulators/buck3";
		i2c1 = "/soc/i2c@11004000";
		i2c2 = "/soc/i2c@11005000";
		pca9545 = "/soc/i2c@11005000/i2c-mux@70";
		imux0 = "/soc/i2c@11005000/i2c-mux@70/i2c@0";
		pca9555 = "/soc/i2c@11005000/i2c-mux@70/i2c@0/i2c-gpio-expander@20";
		imux1_sfp1 = "/soc/i2c@11005000/i2c-mux@70/i2c@1";
		imux2_sfp2 = "/soc/i2c@11005000/i2c-mux@70/i2c@2";
		imux3_wifi = "/soc/i2c@11005000/i2c-mux@70/i2c@3";
		spi0 = "/soc/spi@11007000";
		spi_nand = "/soc/spi@11007000/nand@0";
		spi1 = "/soc/spi@11008000";
		spi2 = "/soc/spi@11009000";
		lvts = "/soc/lvts@1100a000";
		ssusb0 = "/soc/usb@11190000";
		ssusb1 = "/soc/usb@11200000";
		mmc0 = "/soc/mmc@11230000";
		pcie2 = "/soc/pcie@11280000";
		pcie_intc2 = "/soc/pcie@11280000/interrupt-controller";
		pcie3 = "/soc/pcie@11290000";
		pcie_intc3 = "/soc/pcie@11290000/interrupt-controller";
		pcie0 = "/soc/pcie@11300000";
		pcie_intc0 = "/soc/pcie@11300000/interrupt-controller";
		pcie1 = "/soc/pcie@11310000";
		pcie_intc1 = "/soc/pcie@11310000/interrupt-controller";
		tphy = "/soc/t-phy@11c50000";
		tphyu2port0 = "/soc/t-phy@11c50000/usb-phy@0";
		tphyu3port0 = "/soc/t-phy@11c50000/usb-phy@700";
		topmisc = "/soc/system-controller@11d10084";
		xsphy = "/soc/xs-phy@11e10000";
		xphyu2port0 = "/soc/xs-phy@11e10000/usb-phy@0";
		xphyu3port0 = "/soc/xs-phy@11e10000/usb-phy@3400";
		xfi_tphy0 = "/soc/phy@11f20000";
		xfi_tphy1 = "/soc/phy@11f30000";
		xfi_pll = "/soc/clock-controller@11f40000";
		lvts_calibration = "/soc/efuse@11f50000/calib@918";
		phy_calibration_p0 = "/soc/efuse@11f50000/calib@940";
		phy_calibration_p1 = "/soc/efuse@11f50000/calib@954";
		phy_calibration_p2 = "/soc/efuse@11f50000/calib@968";
		phy_calibration_p3 = "/soc/efuse@11f50000/calib@97c";
		ethsys = "/soc/clock-controller@15000000";
		switch = "/soc/switch@15020000";
		gsw_port0 = "/soc/switch@15020000/ports/port@0";
		gsw_port1 = "/soc/switch@15020000/ports/port@1";
		gsw_port2 = "/soc/switch@15020000/ports/port@2";
		gsw_port3 = "/soc/switch@15020000/ports/port@3";
		gsw_phy0 = "/soc/switch@15020000/mdio/ethernet-phy@0";
		gsw_phy0_led0 = "/soc/switch@15020000/mdio/ethernet-phy@0/leds/led@0";
		gsw_phy0_led1 = "/soc/switch@15020000/mdio/ethernet-phy@0/leds/led@1";
		gsw_phy1 = "/soc/switch@15020000/mdio/ethernet-phy@1";
		gsw_phy1_led0 = "/soc/switch@15020000/mdio/ethernet-phy@1/leds/led@0";
		gsw_phy1_led1 = "/soc/switch@15020000/mdio/ethernet-phy@1/leds/led@1";
		gsw_phy2 = "/soc/switch@15020000/mdio/ethernet-phy@2";
		gsw_phy2_led0 = "/soc/switch@15020000/mdio/ethernet-phy@2/leds/led@0";
		gsw_phy2_led1 = "/soc/switch@15020000/mdio/ethernet-phy@2/leds/led@1";
		gsw_phy3 = "/soc/switch@15020000/mdio/ethernet-phy@3";
		gsw_phy3_led0 = "/soc/switch@15020000/mdio/ethernet-phy@3/leds/led@0";
		gsw_phy3_led1 = "/soc/switch@15020000/mdio/ethernet-phy@3/leds/led@1";
		ethwarp = "/soc/clock-controller@15031000";
		eth = "/soc/ethernet@15100000";
		gmac0 = "/soc/ethernet@15100000/mac@0";
		gmac1 = "/soc/ethernet@15100000/mac@1";
		gmac2 = "/soc/ethernet@15100000/mac@2";
		mdio_bus = "/soc/ethernet@15100000/mdio-bus";
		int_2p5g_phy = "/soc/ethernet@15100000/mdio-bus/ethernet-phy@15";
		switchphy0 = "/soc/ethernet@15100000/mdio-bus/switch@16/mdio/switchphy@0";
		switchphy1 = "/soc/ethernet@15100000/mdio-bus/switch@16/mdio/switchphy@1";
		switchphy2 = "/soc/ethernet@15100000/mdio-bus/switch@16/mdio/switchphy@2";
		switchphy3 = "/soc/ethernet@15100000/mdio-bus/switch@16/mdio/switchphy@3";
		eth_sram = "/soc/sram@15400000";
		cpu_thermal = "/thermal-zones/cpu-thermal";
		cpu_trip_crit = "/thermal-zones/cpu-thermal/trips/crit";
		cpu_trip_hot = "/thermal-zones/cpu-thermal/trips/hot";
		cpu_trip_active_high = "/thermal-zones/cpu-thermal/trips/active-high";
		cpu_trip_active_med = "/thermal-zones/cpu-thermal/trips/active-med";
		cpu_trip_active_low = "/thermal-zones/cpu-thermal/trips/active-low";
		fan = "/pwm-fan";
		led_red = "/gpio-leds/sys-led-red";
		led_blue = "/gpio-leds/sys-led-blue";
		reg_1p8v = "/regulator-dvdd1v8";
		reg_3p3v = "/regulator-3v3vd";
		sfp1 = "/sfp1";
		sfp2 = "/sfp2";
	};
};
